# TC37X register map
File version: 1.0.0
CPU: CM4 r0p1, little endian, MPU, FPU, VTOR, 3 interrupt priority bits
Registers are 16-bit, read-write, reset 0x0 unless marked. A register's access mark holds for its fields unless they carry their own. Offsets are from the block's base; [hi:lo] are bit positions; {n}, {i} and the like mark numbered series; 'fields as' and 'values as' point back to an identical list.

## CAN0 — ce_mc_m_can
Base 0xF0200000
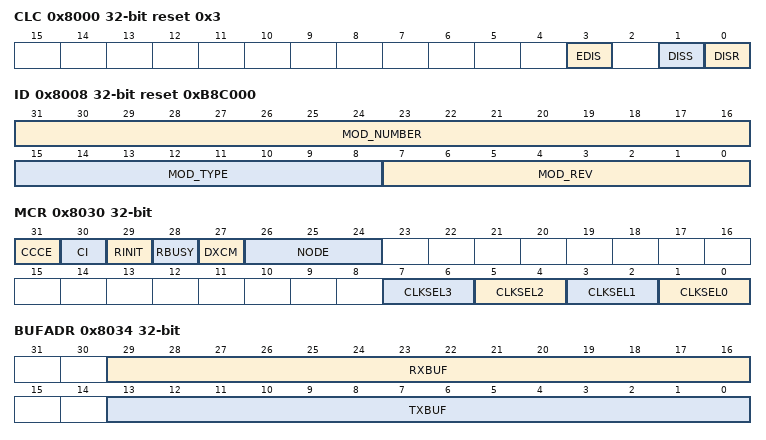
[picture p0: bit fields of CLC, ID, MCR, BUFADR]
0x8000 CLC 32-bit reset 0x3 — CAN Clock Control Register
  [3] EDIS — Sleep Mode Disable Control - EDIS
  [1] DISS ro — Module Disable Status Bit - DISS
  [0] DISR — Module Disable Request Bit - DISR
0x8008 ID 32-bit ro reset 0xB8C000 (reset mask 0xFFFFFF00) — Module Identification Register
  [31:16] MOD_NUMBER — Module Number Value - MOD_NUMBER
  [15:8] MOD_TYPE — Module Type - MOD_TYPE
  [7:0] MOD_REV — Module Revision Number - MOD_REV
0x8030 MCR 32-bit — Module Control Register
  [31] CCCE — Clock and RAM Change Enable - CCCE
  [30] CI — Change Init - CI
  [29] RINIT — RAM Init - RINIT
  [28] RBUSY ro — RAM BUSY - RBUSY
  [27] DXCM — Debug Over CAN Messages Enable - DXCM
  [26:24] NODE — Node - NODE
  [2n+1:2n] CLKSEL{n} (n=0..3) — Clock Select {n} - CLKSEL{n}
0x8034 BUFADR 32-bit — Buffer receive address and transmit address
  [29:16] RXBUF — Receive Buffer start address - RXBUF
  [13:0] TXBUF — Transmit Buffer start address - TXBUF
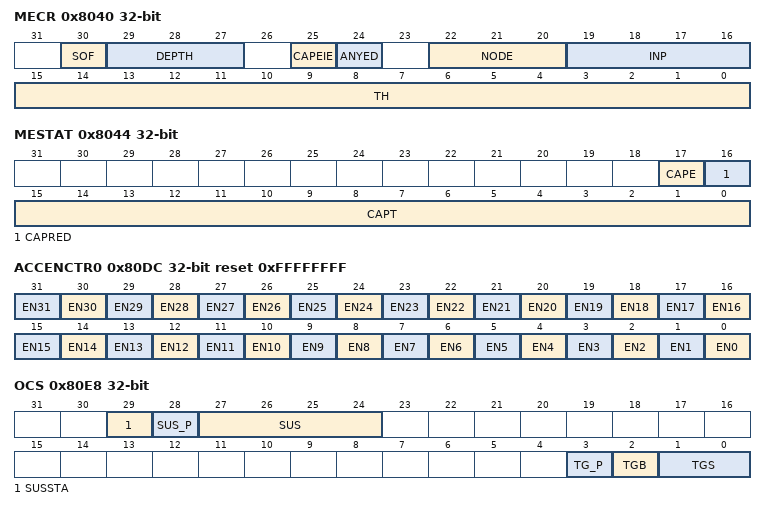
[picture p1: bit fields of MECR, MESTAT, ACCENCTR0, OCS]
0x8040 MECR 32-bit — Measure Control Register
  [30] SOF — Start Of Frame - SOF
  [29:27] DEPTH — Digital Glitch Filter Depth - DEPTH
  [25] CAPEIE — Capture Event Interrupt Enable - CAPEIE
  [24] ANYED — Any Edge - ANYED
  [22:20] NODE — Node - NODE
  [19:16] INP — Interrupt Node Pointer - INP
  [15:0] TH — Threshold - TH
0x8044 MESTAT 32-bit — Measure Status Register
  [17] CAPE — Capture Event - CAPE
  [16] CAPRED ro — Captured Rising Edge - CAPRED
  [15:0] CAPT ro — Captured Timer - CAPT
0x80DC ACCENCTR0 32-bit reset 0xFFFFFFFF — Access Enable Register Control 0
  [n] EN{n} (n=0..31) — Access Enable for Master TAG ID {n} - EN{n}
0x80E8 OCS 32-bit — OCDS Control and Status
  [29] SUSSTA ro — Suspend State - SUSSTA
  [28] SUS_P wo — SUS Write Protection - SUS_P
  [27:24] SUS — OCDS Suspend Control - SUS
  [3] TG_P wo — TGS, TGB Write Protection - TG_P
  [2] TGB — OTGB0/1 Bus Select - TGB
  [1:0] TGS — Trigger Set for OTGB0/1 - TGS
0x80EC KRSTCLR 32-bit wo — Kernel Reset Status Clear Register
  [0] CLR — Kernel Reset Status Clear - CLR
0x80F0 KRST1 32-bit — Kernel Reset Register 1
  [0] RST — Kernel Reset - RST
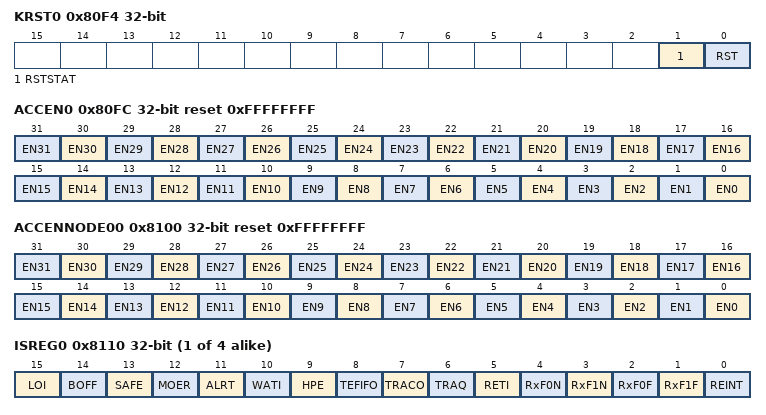
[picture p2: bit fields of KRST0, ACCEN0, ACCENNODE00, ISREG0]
0x80F4 KRST0 32-bit — Kernel Reset Register 0
  [1] RSTSTAT ro — Kernel Reset Status - RSTSTAT
  [0] RST — Kernel Reset - RST
0x80FC ACCEN0 32-bit reset 0xFFFFFFFF — Access Enable Register 0
  [n] EN{n} (n=0..31) — Access Enable for Master TAG ID {n} - EN{n}
0x8100 ACCENNODE00 32-bit reset 0xFFFFFFFF — Access Enable Register CAN Node 0 0
  [n] EN{n} (n=0..31) — Access Enable for Master TAG ID {n} - EN{n}
{0x8108+0x400*i} STARTADR{i} 32-bit (i=0..3) — Start Address Node {i}
  [15:2] START — Message RAM start - START
{0x810C+0x400*i} ENDADR{i} 32-bit (i=0..3) — End Address Node {i}
  [15:2] END — Message RAM end - END
{0x8110+0x400*i} ISREG{i} 32-bit ro (i=0..3) — Interrupt Signalling Register {i}
  [15] LOI — Last Error Interrupt - LOI
  [14] BOFF — Bus Off Interrupt - BOFF
  [13] SAFE — The safety counter interrupt ELO - SAFE
  [12] MOER — Module error interrupt - MOER
  [11] ALRT — An alert interrupt - ALRT
  [10] WATI — A watermark interrupt has been reached - WATI
  [9] HPE — A high priority event interrupt - HPE
  [8] TEFIFO — A Transmit Event FIFO Incident interrupt - TEFIFO
  [7] TRACO — A transmission control event interrupt - TRACO
  [6] TRAQ — A transmission queue event interrupt - TRAQ
  [5] RETI — A receive timeout event interrupt - RETI
  [4] RxF0N — Receive FIFO0 got a new message interrupt - RxF0N
  [3] RxF1N — Receive FIFO1 got a new message interrupt - RxF1N
  [2] RxF0F — Receive FIFO0 is full interrupt - RxF0F
  [1] RxF1F — Receive FIFO1 is full interrupt - RxF1F
  [0] REINT — A message stored in a receive buffer interrupt - REINT
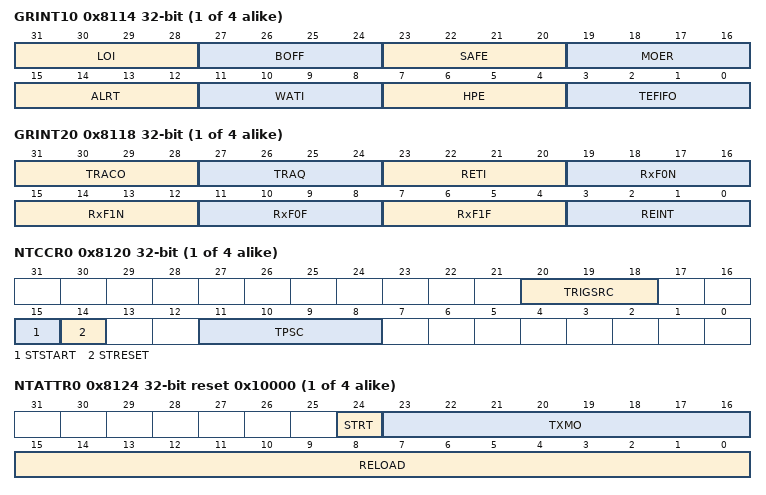
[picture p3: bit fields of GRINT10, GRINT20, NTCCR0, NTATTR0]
{0x5914+0x400*i} GRINT{i} 32-bit (i=10..13) — Interrupt routing for Groups 1 {i-10}
  [31:28] LOI — Last Error Interrupts - LOI
  [27:24] BOFF — Bus Off has been reached - BOFF
  [23:20] SAFE — Safety counter overflow - SAFE
  [19:16] MOER — Module errors - MOER
  [15:12] ALRT — ALERTS - ALRT
  [11:8] WATI — Watermark interrupts - WATI
  [7:4] HPE — High Priority Events - HPE
  [3:0] TEFIFO — Transmit Event FIFO Incidents - TEFIFO
{0x3118+0x400*i} GRINT{i} 32-bit (i=20..23) — Interrupt routing for Groups 2 {i-20}
  [31:28] TRACO — Interrupts of the transmission control - TRACO
  [27:24] TRAQ — Transmission Queue Events - TRAQ
  [23:20] RETI — Receive Timeouts - RETI
  [19:16] RxF0N — IR.RF0N - RxF0N
  [15:12] RxF1N — IR.RF1N - RxF1N
  [11:8] RxF0F — IR.RF0F - RxF0F
  [7:4] RxF1F — IR.RF1F - RxF1F
  [3:0] REINT — Message stored in dedicated receive buffer interrupt (IR.DRX) - REINT
{0x8120+0x400*i} NTCCR{i} 32-bit (i=0..3) — Node {i} Timer Clock Control Register
  [20:18] TRIGSRC — Trigger Source - TRIGSRC
  [15] STSTART — Stamping Start - STSTART
  [14] STRESET — Stamping Reset - STRESET
  [11:8] TPSC — Timer Prescaler - TPSC
{0x8124+0x400*i} NTATTR{i} 32-bit reset 0x10000 (i=0..3) — Node {i} Timer A Transmit Trigger Register
  [24] STRT — Timer Start - STRT
  [23:16] TXMO ro — Transmit Message Object - TXMO
  [15:0] RELOAD — Reload Value - RELOAD
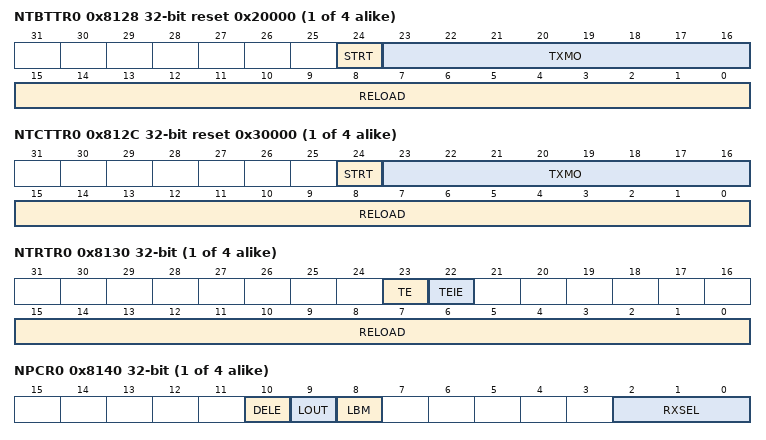
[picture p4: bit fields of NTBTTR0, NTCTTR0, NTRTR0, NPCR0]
{0x8128+0x400*i} NTBTTR{i} 32-bit reset 0x20000 (i=0..3) — Node {i} Timer B Transmit Trigger Register
  fields as NTATTR0
{0x812C+0x400*i} NTCTTR{i} 32-bit reset 0x30000 (i=0..3) — Node {i} Timer C Transmit Trigger Register
  fields as NTATTR0
{0x8130+0x400*i} NTRTR{i} 32-bit (i=0..3) — Node {i} Timer Receive Timeout Register
  [23] TE — Timer Event - TE
  [22] TEIE — Timer Event Interrupt Enable - TEIE
  [15:0] RELOAD — Reload Value - RELOAD
{0x8140+0x400*i} NPCR{i} 32-bit (i=0..3) — Node {i} Port Control Register
  [10] DELE — Enable destructive read on ECR{i}.CEL - DELE
  [9] LOUT — Loop Back Mode Out - LOUT
  [8] LBM — Loop-Back Mode - LBM
  [2:0] RXSEL — Receive Select - RXSEL
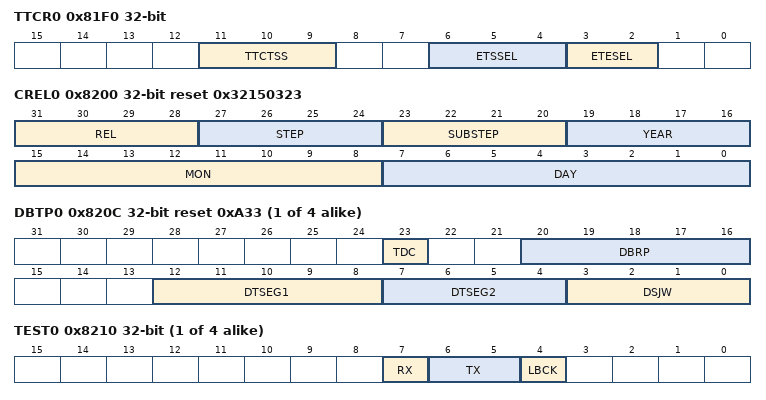
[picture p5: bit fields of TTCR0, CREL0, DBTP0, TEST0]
0x81F0 TTCR0 32-bit — Time Trigger Control Register
  [11:9] TTCTSS — TTCapture Time Trigger Source Select - TTCTSS
  [6:4] ETSSEL — External Trigger Source Selection - ETSSEL
  [3:2] ETESEL — External Trigger Event Selection - ETESEL
0x8200 CREL0 32-bit ro reset 0x32150323 — Core Release Register 0
  [31:28] REL — Core Release - REL
  [27:24] STEP — Step of Core Release - STEP
  [23:20] SUBSTEP — Sub-step of Core Release - SUBSTEP
  [19:16] YEAR — Time Stamp Year
  [15:8] MON — Time Stamp Month
  [7:0] DAY — Time Stamp Day
{0x8204+0x400*i} ENDN{i} 32-bit ro reset 0x87654321 (i=0..3) — Endian Register {i}
  [31:0] ETV — Endianness Test Value - ETV
{0x820C+0x400*i} DBTP{i} 32-bit reset 0xA33 (i=0..3) — Data Bit Timing & Prescaler Register {i}
  [23] TDC — Transmitter Delay Compensation - TDC
  [20:16] DBRP — Data Baud Rate Prescaler - DBRP
  [12:8] DTSEG1 — Data time segment before sample point - DTSEG1
  [7:4] DTSEG2 — Data time segment after sample point - DTSEG2
  [3:0] DSJW — Data (Re) Synchronization Jump Width - DSJW
{0x8210+0x400*i} TEST{i} 32-bit (reset mask 0xFFFFFF7F) (i=0..3) — Test Register {i}
  [7] RX ro — Receive Pin - RX
  [6:5] TX — Control of Transmit Pin - TX
  [4] LBCK — Loop Back Mode - LBCK
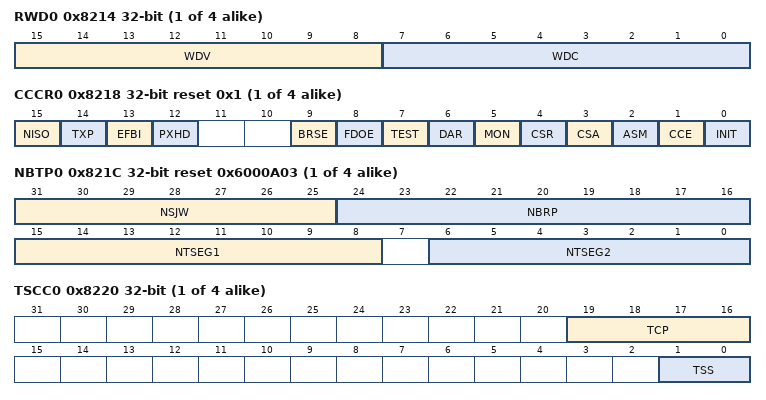
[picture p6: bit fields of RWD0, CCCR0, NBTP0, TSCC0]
{0x8214+0x400*i} RWD{i} 32-bit (i=0..3) — RAM Watchdog {i}
  [15:8] WDV ro — Watchdog Value - WDV
  [7:0] WDC — Watchdog Configuration - WDC
{0x8218+0x400*i} CCCR{i} 32-bit reset 0x1 (i=0..3) — CC Control Register {i}
  [15] NISO — Non ISO Operation - NISO
  [14] TXP — Transmit Pause - TXP
  [13] EFBI — Edge Filtering during Bus Integration - EFBI
  [12] PXHD — Protocol Exception Handling Disable - PXHD
  [9] BRSE — Bit Rate Switch Enable - BRSE
  [8] FDOE — FD Operation Enable - FDOE
  [7] TEST — Test Mode Enable - TEST
  [6] DAR — Disable Automatic Retransmission - DAR
  [5] MON — Bus Monitoring Mode - MON
  [4] CSR — Clock Stop Request - CSR
  [3] CSA ro — Clock Stop Acknowledge - CSA
  [2] ASM — Restricted Operation Mode - ASM
  [1] CCE — Configuration Change Enable - CCE
  [0] INIT — Initialization - INIT
{0x821C+0x400*i} NBTP{i} 32-bit reset 0x6000A03 (i=0..3) — Nominal Bit Timing & Prescaler Register {i}
  [31:25] NSJW — (Re) Synchronization Jump Width - NSJW
  [24:16] NBRP — Baud Rate Prescaler - NBRP
  [15:8] NTSEG1 — Nominal Time segment before sample point - NTSEG1
  [6:0] NTSEG2 — Nominal Time segment after sample point - NTSEG2
{0x8220+0x400*i} TSCC{i} 32-bit (i=0..3) — Timestamp Counter Configuration {i}
  [19:16] TCP — Timestamp Counter Prescaler - TCP
  [1:0] TSS — Time segment before sample point - TSS
{0x8224+0x400*i} TSCV{i} 32-bit (i=0..3) — Timestamp Counter Value {i}
  [15:0] TSC — Timestamp Counter - TSC
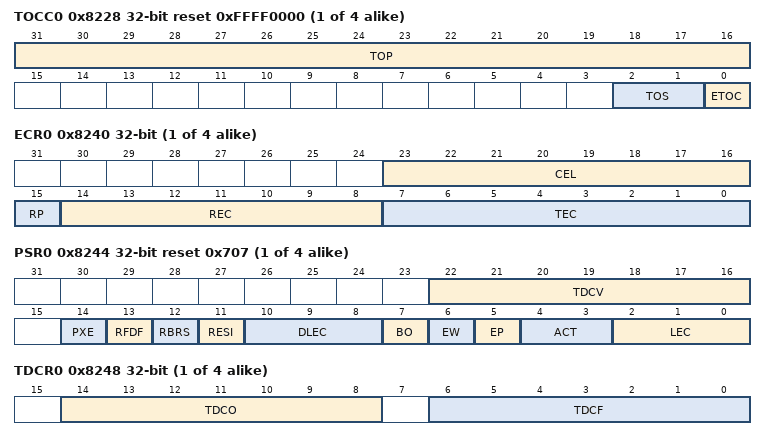
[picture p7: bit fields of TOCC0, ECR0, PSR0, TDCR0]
{0x8228+0x400*i} TOCC{i} 32-bit reset 0xFFFF0000 (i=0..3) — Timeout Counter Configuration {i}
  [31:16] TOP — Timeout Period - TOP
  [2:1] TOS — Timeout Select - TOS
  [0] ETOC — Enable Timeout Counter - ETOC
{0x822C+0x400*i} TOCV{i} 32-bit reset 0xFFFF (i=0..3) — Timeout Counter Value {i}
  [15:0] TOC — Timeout Counter - TOC
{0x8240+0x400*i} ECR{i} 32-bit ro (i=0..3) — Error Counter Register {i}
  [23:16] CEL — CAN Error Logging - CEL
  [15] RP — Receive Error Passive - RP
  [14:8] REC — Receive Error Counter - REC
  [7:0] TEC — Transmit Error Counter - TEC
{0x8244+0x400*i} PSR{i} 32-bit ro reset 0x707 (i=0..3) — Protocol Status Register {i}
  [22:16] TDCV — Transmitter Delay Compensation Value - TDCV
  [14] PXE — Protocol Exception Event - PXE
  [13] RFDF — Received a CAN FD Message - RFDF
  [12] RBRS — BRS flag of last received CAN FD Message - RBRS
  [11] RESI — ESI flag of last received CAN FD Message - RESI
  [10:8] DLEC — Data Phase Last Error Code - DLEC
  [7] BO — Bus_Off Status - BO
  [6] EW — Warning Status - EW
  [5] EP — Error Passive - EP
  [4:3] ACT — Activity - ACT
  [2:0] LEC — Last Error Code - LEC
{0x8248+0x400*i} TDCR{i} 32-bit (i=0..3) — Transmitter Delay Compensation Register {i}
  [14:8] TDCO — Transmitter Delay Compensation Offset - TDCO
  [6:0] TDCF — Transmitter Delay Compensation Filter Window Length - TDCF
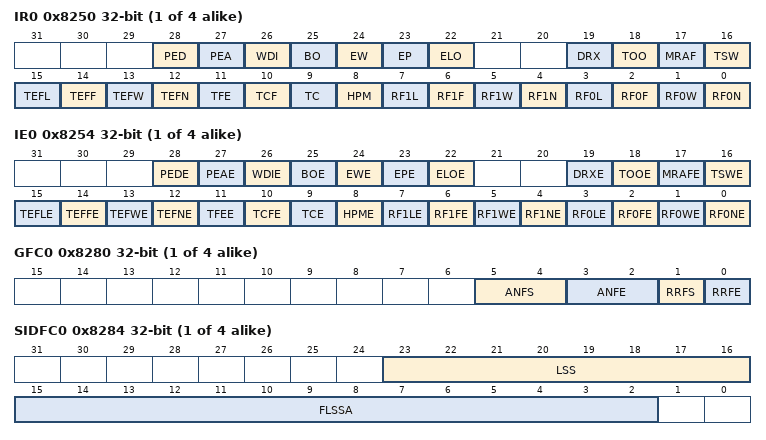
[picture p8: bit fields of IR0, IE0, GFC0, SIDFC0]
{0x8250+0x400*i} IR{i} 32-bit (i=0..3) — Interrupt Register {i}
  [28] PED — Protocol Error in Data Phase - PED
  [27] PEA — Protocol Error in Arbitration Phase - PEA
  [26] WDI — Watchdog Interrupt - WDI
  [25] BO — Bus_Off Status - BO
  [24] EW — Warning Status - EW
  [23] EP — Error Passive - EP
  [22] ELO — Error Logging Overflow - ELO
  [19] DRX — Message stored to Dedicated Rx Buffer - DRX
  [18] TOO — Timeout Occurred - TOO
  [17] MRAF — Message RAM Access Failure - MRAF
  [16] TSW — Timestamp Wraparound - TSW
  [15] TEFL — Tx Event FIFO Element Lost - TEFL
  [14] TEFF — Tx Event FIFO Full - TEFF
  [13] TEFW — Tx Event FIFO Watermark Reached - TEFW
  [12] TEFN — Tx Event FIFO New Entry - TEFN
  [11] TFE — Tx FIFO Empty - TFE
  [10] TCF — Transmission Cancellation Finished - TCF
  [9] TC — Transmission Completed - TC
  [8] HPM — High Priority Message - HPM
  [7] RF1L — Rx FIFO 1 Message Lost - RF1L
  [6] RF1F — Rx FIFO 1 Full - RF1F
  [5] RF1W — Rx FIFO 1 Watermark Reached - RF1W
  [4] RF1N — Rx FIFO 1 New Message - RF1N
  [3] RF0L — Rx FIFO 0 Message Lost - RF0L
  [2] RF0F — Rx FIFO 0 Full - RF0F
  [1] RF0W — Rx FIFO 0 Watermark Reached - RF0W
  [0] RF0N — Rx FIFO 0 New Message - RF0N
{0x8254+0x400*i} IE{i} 32-bit (i=0..3) — Interrupt Enable {i}
  [28] PEDE — Protocol Error in Data Phase Enable - PEDE
  [27] PEAE — Protocol Error in Arbitration Phase Enable - PEAE
  [26] WDIE — Watchdog Interrupt Enable - WDIE
  [25] BOE — Bus_Off Status Interrupt Enable - BOE
  [24] EWE — Warning Status Interrupt Enable - EWE
  [23] EPE — Error Passive Interrupt Enable - EPE
  [22] ELOE — Error Logging Overflow Interrupt Enable - ELOE
  [19] DRXE — Message stored to Dedicated Rx Buffer Interrupt Enable - DRXE
  [18] TOOE — Timeout Occurred Interrupt Enable - TOOE
  [17] MRAFE — Message RAM Access Failure Interrupt Enable - MRAFE
  [16] TSWE — Timestamp Wraparound Interrupt Enable - TSWE
  [15] TEFLE — Tx Event FIFO Element Lost Interrupt Enable - TEFLE
  [14] TEFFE — Tx Event FIFO Full Interrupt Enable - TEFFE
  [13] TEFWE — Tx Event FIFO Watermark Reached Interrupt Enable - TEFWE
  [12] TEFNE — Tx Event FIFO New Entry Interrupt Enable - TEFNE
  [11] TFEE — Tx FIFO Empty Interrupt Enable - TFEE
  [10] TCFE — Transmission Cancellation Finished Interrupt Enable - TCFE
  [9] TCE — Transmission Completed Interrupt Enable - TCE
  [8] HPME — High Priority Message Interrupt Enable - HPME
  [7] RF1LE — Rx FIFO 1 Message Lost Interrupt Enable - RF1LE
  [6] RF1FE — Rx FIFO 1 Full Interrupt Enable - RF1FE
  [5] RF1WE — Rx FIFO 1 Watermark Reached Interrupt Enable - RF1WE
  [4] RF1NE — Rx FIFO 1 New Message Interrupt Enable - RF1NE
  [3] RF0LE — Rx FIFO 0 Message Lost Interrupt Enable - RF0LE
  [2] RF0FE — Rx FIFO 0 Full Interrupt Enable - RF0FE
  [1] RF0WE — Rx FIFO 0 Watermark Reached Interrupt Enable - RF0WE
  [0] RF0NE — Rx FIFO 0 New Message Interrupt Enable - RF0NE
{0x8280+0x400*i} GFC{i} 32-bit (i=0..3) — Global Filter Configuration {i}
  [5:4] ANFS — Accept Non-matching Frames Standard - ANFS
  [3:2] ANFE — Accept Non-matching Frames Extended - ANFE
  [1] RRFS — Reject Remote Frames Standard - RRFS
  [0] RRFE — Reject Remote Frames Extended - RRFE
{0x8284+0x400*i} SIDFC{i} 32-bit (i=0..3) — Standard ID Filter Configuration {i}
  [23:16] LSS — List Size Standard - LSS
  [15:2] FLSSA — Filter List Standard Start Address - FLSSA
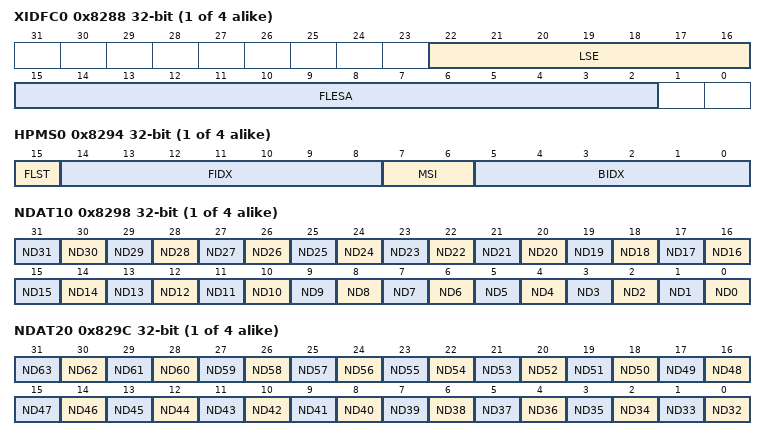
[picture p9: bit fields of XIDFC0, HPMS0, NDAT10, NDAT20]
{0x8288+0x400*i} XIDFC{i} 32-bit (i=0..3) — Extended ID Filter Configuration {i}
  [22:16] LSE — List Size Extended - LSE
  [15:2] FLESA — Filter List Extended Start Address - FLESA
{0x8290+0x400*i} XIDAM{i} 32-bit reset 0x1FFFFFFF (i=0..3) — Extended ID AND Mask {i}
  [28:0] EIDM — Extended ID Mask - EIDM
{0x8294+0x400*i} HPMS{i} 32-bit ro (i=0..3) — High Priority Message Status {i}
  [15] FLST — Filter List - FLST
  [14:8] FIDX — Filter Index - FIDX
  [7:6] MSI — Message Storage Indicator - MSI
  [5:0] BIDX — Buffer Index - BIDX
{0x5A98+0x400*i} NDAT{i} 32-bit (i=10..13) — New Data 1 {i-10}
  [n] ND{n} (n=0..31) — New Data in Rx Buffer {n} - ND
{0x329C+0x400*i} NDAT{i} 32-bit (i=20..23) — New Data 2 {i-20}
  [n-32] ND{n} (n=32..63) — New Data in Rx Buffer {n} - ND
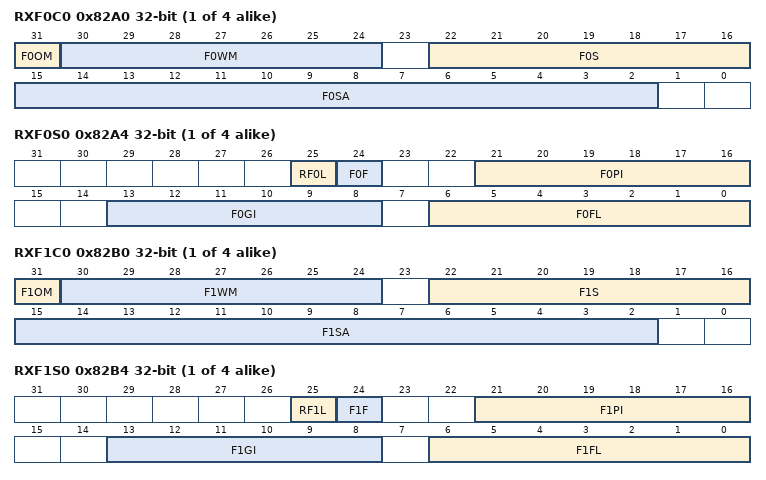
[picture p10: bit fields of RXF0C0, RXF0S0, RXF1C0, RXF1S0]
{0x82A0+0x400*i} RXF0C{i} 32-bit (i=0..3) — Rx FIFO 0 Configuration {i}
  [31] F0OM — FIFO 0 Operation Mode - F0OM
  [30:24] F0WM — Rx FIFO 0 Watermark - F0WM
  [22:16] F0S — Rx FIFO 0 Size - F0S
  [15:2] F0SA — Rx FIFO 0 Start Address - F0SA
{0x82A4+0x400*i} RXF0S{i} 32-bit ro (i=0..3) — Rx FIFO 0 Status {i}
  [25] RF0L — Rx FIFO 0 Message Lost - RF0L
  [24] F0F — Rx FIFO 0 Full - F0F
  [21:16] F0PI — Rx FIFO 0 Put Index - F0PI
  [13:8] F0GI — Rx FIFO 0 Get Index - F0GI
  [6:0] F0FL — Rx FIFO 0 Fill Level - F0FL
{0x82A8+0x400*i} RXF0A{i} 32-bit (i=0..3) — Rx FIFO 0 Acknowledge {i}
  [5:0] F0AI — Rx FIFO 0 Acknowledge Index - F0AI
{0x82AC+0x400*i} RXBC{i} 32-bit (i=0..3) — Rx Buffer Configuration {i}
  [15:2] RBSA — Rx Buffer Start Address - RBSA
{0x82B0+0x400*i} RXF1C{i} 32-bit (i=0..3) — Rx FIFO 1 Configuration {i}
  [31] F1OM — FIFO 1 Operation Mode - F1OM
  [30:24] F1WM — Rx FIFO 1 Watermark - F1WM
  [22:16] F1S — Rx FIFO 1 Size - F1S
  [15:2] F1SA — Rx FIFO 1 Start Address - F1SA
{0x82B4+0x400*i} RXF1S{i} 32-bit ro (i=0..3) — Rx FIFO 1 Status {i}
  [25] RF1L — Rx FIFO 1 Message Lost - RF1L
  [24] F1F — Rx FIFO 1 Full - F1F
  [21:16] F1PI — Rx FIFO 1 Put Index - F1PI
  [13:8] F1GI — Rx FIFO 1 Get Index - F1GI
  [6:0] F1FL — Rx FIFO 1 Fill Level - F1FL
{0x82B8+0x400*i} RXF1A{i} 32-bit (i=0..3) — Rx FIFO 1 Acknowledge {i}
  [5:0] F1AI — Rx FIFO 1 Acknowledge Index - F1AI
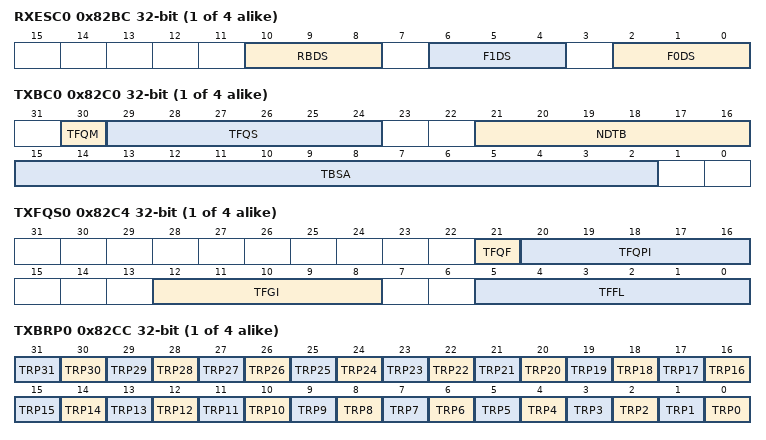
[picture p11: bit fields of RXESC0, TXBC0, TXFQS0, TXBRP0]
{0x82BC+0x400*i} RXESC{i} 32-bit (i=0..3) — Rx Buffer/FIFO Element Size Configuration {i}
  [10:8] RBDS — Rx Buffer Data Field Size - RBDS
  [6:4] F1DS — Rx FIFO 1 Data Field Size - F1DS
  [2:0] F0DS — Rx FIFO 0 Data Field Size - F0DS
{0x82C0+0x400*i} TXBC{i} 32-bit (i=0..3) — Tx Buffer Configuration {i}
  [30] TFQM — Tx FIFO/Queue Mode - TFQM
  [29:24] TFQS — Transmit FIFO/Queue Size - TFQS
  [21:16] NDTB — Number of Dedicated Transmit Buffers - NDTB
  [15:2] TBSA — Tx Buffers Start Address - TBSA
{0x82C4+0x400*i} TXFQS{i} 32-bit ro (i=0..3) — Tx FIFO/Queue Status {i}
  [21] TFQF — Tx FIFO/Queue Full - TFQF
  [20:16] TFQPI — Tx FIFO/Queue Put Index - TFQPI
  [12:8] TFGI — Tx FIFO Get Index - TFGI
  [5:0] TFFL — Tx FIFO Free Level - TFFL
{0x82C8+0x400*i} TXESC{i} 32-bit (i=0..3) — Tx Buffer Element Size Configuration {i}
  [2:0] TBDS — Tx Buffer Data Field Size - TBDS
{0x82CC+0x400*i} TXBRP{i} 32-bit ro (i=0..3) — Tx Buffer Request Pending {i}
  [n] TRP{n} (n=0..31) — Transmission Request Pending Tx Buffer {n} - TRP
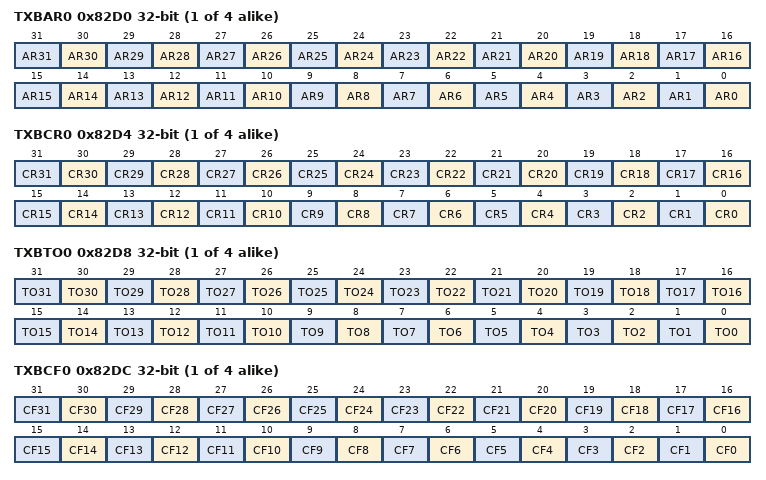
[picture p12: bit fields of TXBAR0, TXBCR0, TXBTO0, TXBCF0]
{0x82D0+0x400*i} TXBAR{i} 32-bit (i=0..3) — Tx Buffer Add Request {i}
  [n] AR{n} (n=0..31) — Add Request Tx Buffer {n} - AR
{0x82D4+0x400*i} TXBCR{i} 32-bit (i=0..3) — Tx Buffer Cancellation Request {i}
  [n] CR{n} (n=0..31) — Cancellation Request Tx Buffer {n} - CR
{0x82D8+0x400*i} TXBTO{i} 32-bit ro (i=0..3) — Tx Buffer Transmission Occurred {i}
  [n] TO{n} (n=0..31) — Transmission Occurred Tx Buffer {n} - TO
{0x82DC+0x400*i} TXBCF{i} 32-bit ro (i=0..3) — Tx Buffer Cancellation Finished {i}
  [n] CF{n} (n=0..31) — Cancellation Finished Tx Buffer {n} - CF
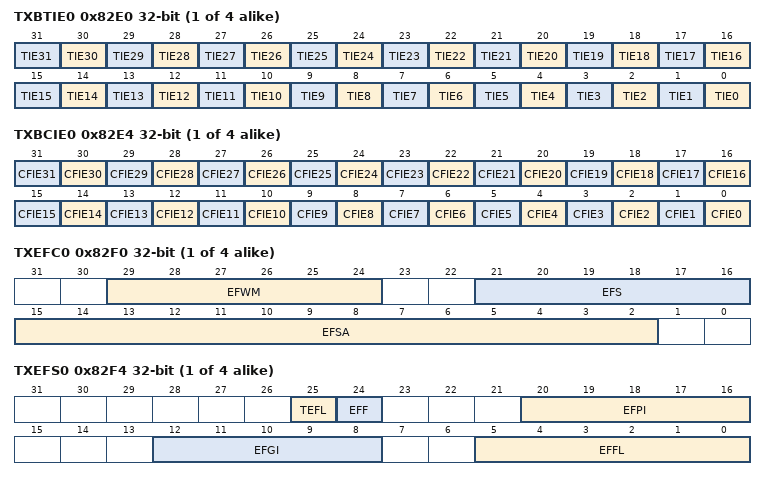
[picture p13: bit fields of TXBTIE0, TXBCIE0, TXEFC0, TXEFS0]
{0x82E0+0x400*i} TXBTIE{i} 32-bit (i=0..3) — Tx Buffer Transmission Interrupt Enable {i}
  [n] TIE{n} (n=0..31) — Transmission Interrupt Enable Tx Buffer {n} - TIE
{0x82E4+0x400*i} TXBCIE{i} 32-bit (i=0..3) — Tx Buffer Cancellation Finished Interrupt Enable {i}
  [n] CFIE{n} (n=0..31) — Cancellation Finished Interrupt Enable Tx Buffer {n} - CFIE
{0x82F0+0x400*i} TXEFC{i} 32-bit (i=0..3) — Tx Event FIFO Configuration {i}
  [29:24] EFWM — Event FIFO Watermark - EFWM
  [21:16] EFS — Event FIFO Size - EFS
  [15:2] EFSA — Event FIFO Start Address - EFSA
{0x82F4+0x400*i} TXEFS{i} 32-bit ro (i=0..3) — Tx Event FIFO Status {i}
  [25] TEFL — Tx Event FIFO Element Lost - TEFL
  [24] EFF — Event FIFO Full - EFF
  [20:16] EFPI — Event FIFO Put Index - EFPI
  [12:8] EFGI — Event FIFO Get Index - EFGI
  [5:0] EFFL — Event FIFO Fill Level - EFFL
{0x82F8+0x400*i} TXEFA{i} 32-bit (i=0..3) — Tx Event FIFO Acknowledge {i}
  [4:0] EFAI — Event FIFO Acknowledge Index - EFAI
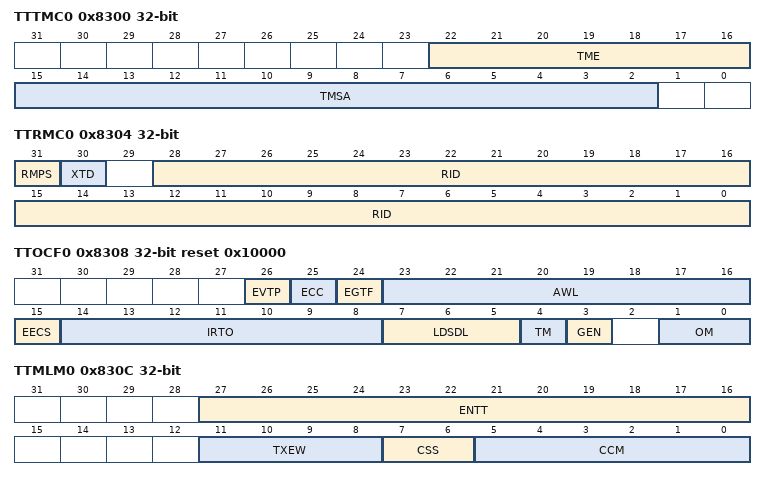
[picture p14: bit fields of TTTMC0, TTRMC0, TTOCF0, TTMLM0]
0x8300 TTTMC0 32-bit — TT Trigger Memory Configuration 0
  [22:16] TME — Trigger Memory Elements - TME
  [15:2] TMSA — Trigger Memory Start Address - TMSA
0x8304 TTRMC0 32-bit — TT Reference Message Configuration 0
  [31] RMPS — Reference Message Payload Select - RMPS
  [30] XTD — Extended Identifier - XTD
  [28:0] RID — Reference Identifier - RID
0x8308 TTOCF0 32-bit reset 0x10000 — TT Operation Configuration 0
  [26] EVTP — Event Trigger Polarity - EVTP
  [25] ECC — Enable Clock Calibration - ECC
  [24] EGTF — Enable Global Time Filtering - EGTF
  [23:16] AWL — Application Watchdog Limit - AWL
  [15] EECS — Enable External Clock Synchronization - EECS
  [14:8] IRTO — Initial Reference Trigger Offset - IRTO
  [7:5] LDSDL — LD of Synchronization Deviation Limit - LDSDL
  [4] TM — Time Master - TM
  [3] GEN — Gap Enable - GEN
  [1:0] OM — Operation Mode - OM
0x830C TTMLM0 32-bit — TT Matrix Limits 0
  [27:16] ENTT — Expected Number of Tx Triggers - ENTT
  [11:8] TXEW — Tx Enable Window - TXEW
  [7:6] CSS — Cycle Start Synchronization - CSS
  [5:0] CCM — Cycle Count Max - CCM
0x8310 TURCF0 32-bit reset 0x10000000 — TUR Configuration 0
  [31] ELT — Enable Local Time - ELT
  [29:16] DC — Denominator Configuration - DC
  [15:0] NCL — Numerator Configuration Low - NCL
0x8314 TTOCN0 32-bit — TT Operation Control 0
  [15] LCKC ro — TT Operation Control Register Locked - LCKC
  [13] ESCN — External Synchronization Control - ESCN
  [12] NIG — Next is Gap - NIG
  [11] TMG — Time Mark Gap - TMG
  [10] FGP — Finish Gap - FGP
  [9] GCS — Gap Control Select - GCS
  [8] TTIE — Trigger Time Mark Interrupt Pulse Enable - TTIE
  [7:6] TMC — Register Time Mark Compare - TMC
  [5] RTIE — Register Time Mark Interrupt Pulse Enable - RTIE
  [4:3] SWS — Stop Watch Source - SWS
  [2] SWP — Stop Watch Polarity - SWP
  [1] ECS — External Clock Synchronization - ECS
  [0] SGT — Set Global time - SGT
0x8318 TTGTP0 32-bit — TT Global Time Preset 0
  [31:16] CTP — Cycle Time Target Phase - CTP
  [15:0] TP — Time Preset - TP
0x831C TTTMK0 32-bit — TT Time Mark 0
  [31] LCKM ro — TT Time Mark Register Locked - LCKM
  [22:16] TICC — Time Mark Cycle Code - TICC
  [15:0] TM — Time Mark - TM
0x8320 TTIR0 32-bit — TT Interrupt Register 0
  [18] CER — Configuration Error - CER
  [17] AW — Application Watchdog - AW
  [16] WT — Watch Trigger - WT
  [15] IWT — Initialization Watch Trigger - IWT
  [14] ELC — Error Level Changed - ELC
  [13] SE2 — Scheduling Error 2 - SE2
  [12] SE1 — Scheduling Error 1 - SE1
  [11] TXO — Tx Count Overflow - TXO
  [10] TXU — Tx Count Underflow - TXU
  [9] GTE — Global Time Error - GTE
  [8] GTD — Global Time Discontinuity - GTD
  [7] GTW — Global Time Wrap - GTW
  [6] SWE — Stop Watch Polarity - SWE
  [5] TTMI — Trigger Time Mark Event Internal - TTMI
  [4] RTMI — Register Time Mark Interrupt - RTMI
  [3] SOG — Start of Gap - SOG
  [2] CSM — Change of Synchronization Mode - CSM
  [1] SMC — Start of Matrix Cycle - SMC
  [0] SBC — Start of Basic Cycle - SBC
0x8324 TTIE0 32-bit — TT Interrupt Enable 0
  [18] CERE — Configuration Error Interrupt Enable - CERE
  [17] AWE — Application Watchdog Interrupt Enable - AWE
  [16] WTE — Watch Trigger Interrupt Enable - WTE
  [15] IWTE — Initialization Watch Trigger Interrupt Enable - IWTE
  [14] ELCE — Change Error Level Interrupt Enable - ELCE
  [13] SE2E — Scheduling Error 2 Interrupt Enable - SE2E
  [12] SE1E — Scheduling Error 1 Interrupt Enable - SE1E
  [11] TXOE — Tx Count Overflow Interrupt Enable - TXOE
  [10] TXUE — Tx Count Underflow Interrupt Enable - TXUE
  [9] GTEE — Global Time Error Interrupt Enable - GTEE
  [8] GTDE — Global Time Discontinuity Interrupt Enable - GTDE
  [7] GTWE — Global Time Wrap Interrupt Enable - GTWE
  [6] SWEE — Stop Watch Polarity Interrupt Enable - SWEE
  [5] TTMIE — Trigger Time Mark Event Internal Interrupt Enable - TTMIE
  [4] RTMIE — Register Time Mark Interrupt Enable - RTMIE
  [3] SOGE — Start of Gap Interrupt Enable - SOGE
  [2] CSME — Change of Synchronization Mode Interrupt Enable - CSME
  [1] SMCE — Start of Matrix Cycle Interrupt Enable - SMCE
  [0] SBCE — Start of Basic Cycle Interrupt Enable - SBCE
0x832C TTOST0 32-bit ro reset 0x20000080 — TT Operation Status 0
  [31] SPL — Schedule Phase Lock - SPL
  [30] WECS — Wait for External Clock Synchronization - WECS
  [29] AWE — Application Watchdog Event - AWE
  [28] WFE — Wait for Event - WFE
  [27] GSI — Gap Started Indicator - GSI
  [26:24] TMP — Time Master Priority - TMP
  [23] GFI — Gap Finished Indicator - GFI
  [22] WGTD — Wait for Global Time Discontinuity - WGTD
  [15:8] RTO — Reference Trigger Offset - RTO
  [7] QCS — Quality of Clock Speed - QCS
  [6] QGTP — Quality of Global Time Phase - QGTP
  [5:4] SYS — Synchronization State - SYS
  [3:2] MS — Master State - MS
  [1:0] EL — Error Level - EL
0x8330 TURNA0 32-bit ro reset 0x10000 — TUR Numerator Actual 0
  [17:0] NAV — Numerator Actual Value - NAV
0x8334 TTLGT0 32-bit ro — TT Local & Global Time 0
  [31:16] GT — Global Time - GT
  [15:0] LT — Local Time - LT
0x8338 TTCTC0 32-bit ro reset 0x3F0000 — TT Cycle Time & Count 0
  [21:16] CC — Cycle Count - CC
  [15:0] CT — Cycle Time - CT
0x833C TTCPT0 32-bit ro — TT Capture Time 0
  [31:16] SWV — Stop Watch Value - SWV
  [5:0] CCV — Cycle Count Value - CCV
0x8340 TTCSM0 32-bit ro — TT Cycle Sync Mark 0
  [15:0] CSM — Cycle Sync Mark - CSM
0x8500 ACCENNODE10 32-bit reset 0xFFFFFFFF — Access Enable Register CAN Node 1 0
  [n] EN{n} (n=0..31) — Access Enable for Master TAG ID {n} - EN{n}
{0x8200+0x400*i} CREL{i} 32-bit ro reset 0x32150320 (i=1..3) — Core Release Register {i}
  fields as CREL0
0x8900 ACCENNODE20 32-bit reset 0xFFFFFFFF — Access Enable Register CAN Node 2 0
  [n] EN{n} (n=0..31) — Access Enable for Master TAG ID {n} - EN{n}
0x8D00 ACCENNODE30 32-bit reset 0xFFFFFFFF — Access Enable Register CAN Node 3 0
  [n] EN{n} (n=0..31) — Access Enable for Master TAG ID {n} - EN{n}

## CAN1 — ce_mc_m_can
Base 0xF0210000
Registers as CAN0, without BUFADR, MECR, MESTAT, TTCR0, TTTMC0, TTRMC0, TTOCF0, TTMLM0, TURCF0, TTOCN0, TTGTP0, TTTMK0, TTIR0, TTIE0, TTOST0, TURNA0, TTLGT0, TTCTC0, TTCPT0, TTCSM0; these are added or differ:
0x8030 MCR 32-bit — Module Control Register
  [31] CCCE — Clock and RAM Change Enable - CCCE
  [30] CI — Change Init - CI
  [29] RINIT — RAM Init - RINIT
  [28] RBUSY ro — RAM BUSY - RBUSY
  [2n+1:2n] CLKSEL{n} (n=0..3) — Clock Select {n} - CLKSEL{n}
0x8200 CREL0 32-bit ro reset 0x32150320 — Core Release Register 0
  fields as CAN0.CREL0
